AUTOSAR XML (schema 4-2-2)
package /CDD_CORE0
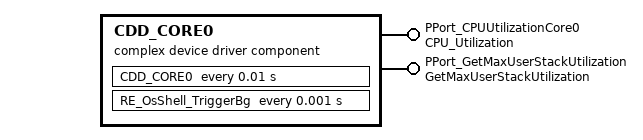
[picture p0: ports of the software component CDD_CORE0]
  complex device driver sw component type CDD_CORE0
    provide port PPort_CPUUtilizationCore0: server-com-spec{operation=CPU_Utilization, queue-length=1}, provided-interface=CPU_Utilization
    provide port PPort_GetMaxUserStackUtilization: provided-interface=GetMaxUserStackUtilization
    behavior SwcInternalBehavior
      operation invoked event OperationInvokedEvent_0: start-on-event=CPUUtilizationCore0, operation=PPort_CPUUtilizationCore0.CPU_Utilization
      timing event TimingEvent_0: start-on-event=CDD_CORE0, period=0.01
      timing event TimingEvent_1: start-on-event=RE_OsShell_TriggerBg, period=0.001
      operation invoked event OperationInvokedEvent_3: start-on-event=GetMaxUserStackUtilization_Core0, operation=PPort_GetMaxUserStackUtilization.GetMaxUserStackUtilization
      4 x runnable:
        CPUUtilizationCore0: symbol=CPUUtilizationCore0_func
          wait point WaitPoint
        CDD_CORE0: symbol=CDD_CORE0_func
        RE_OsShell_TriggerBg: symbol=RE_OsShell_TriggerBg_func
        GetMaxUserStackUtilization_Core0: symbol=GetMaxUserStackUtilization_Core0_func
